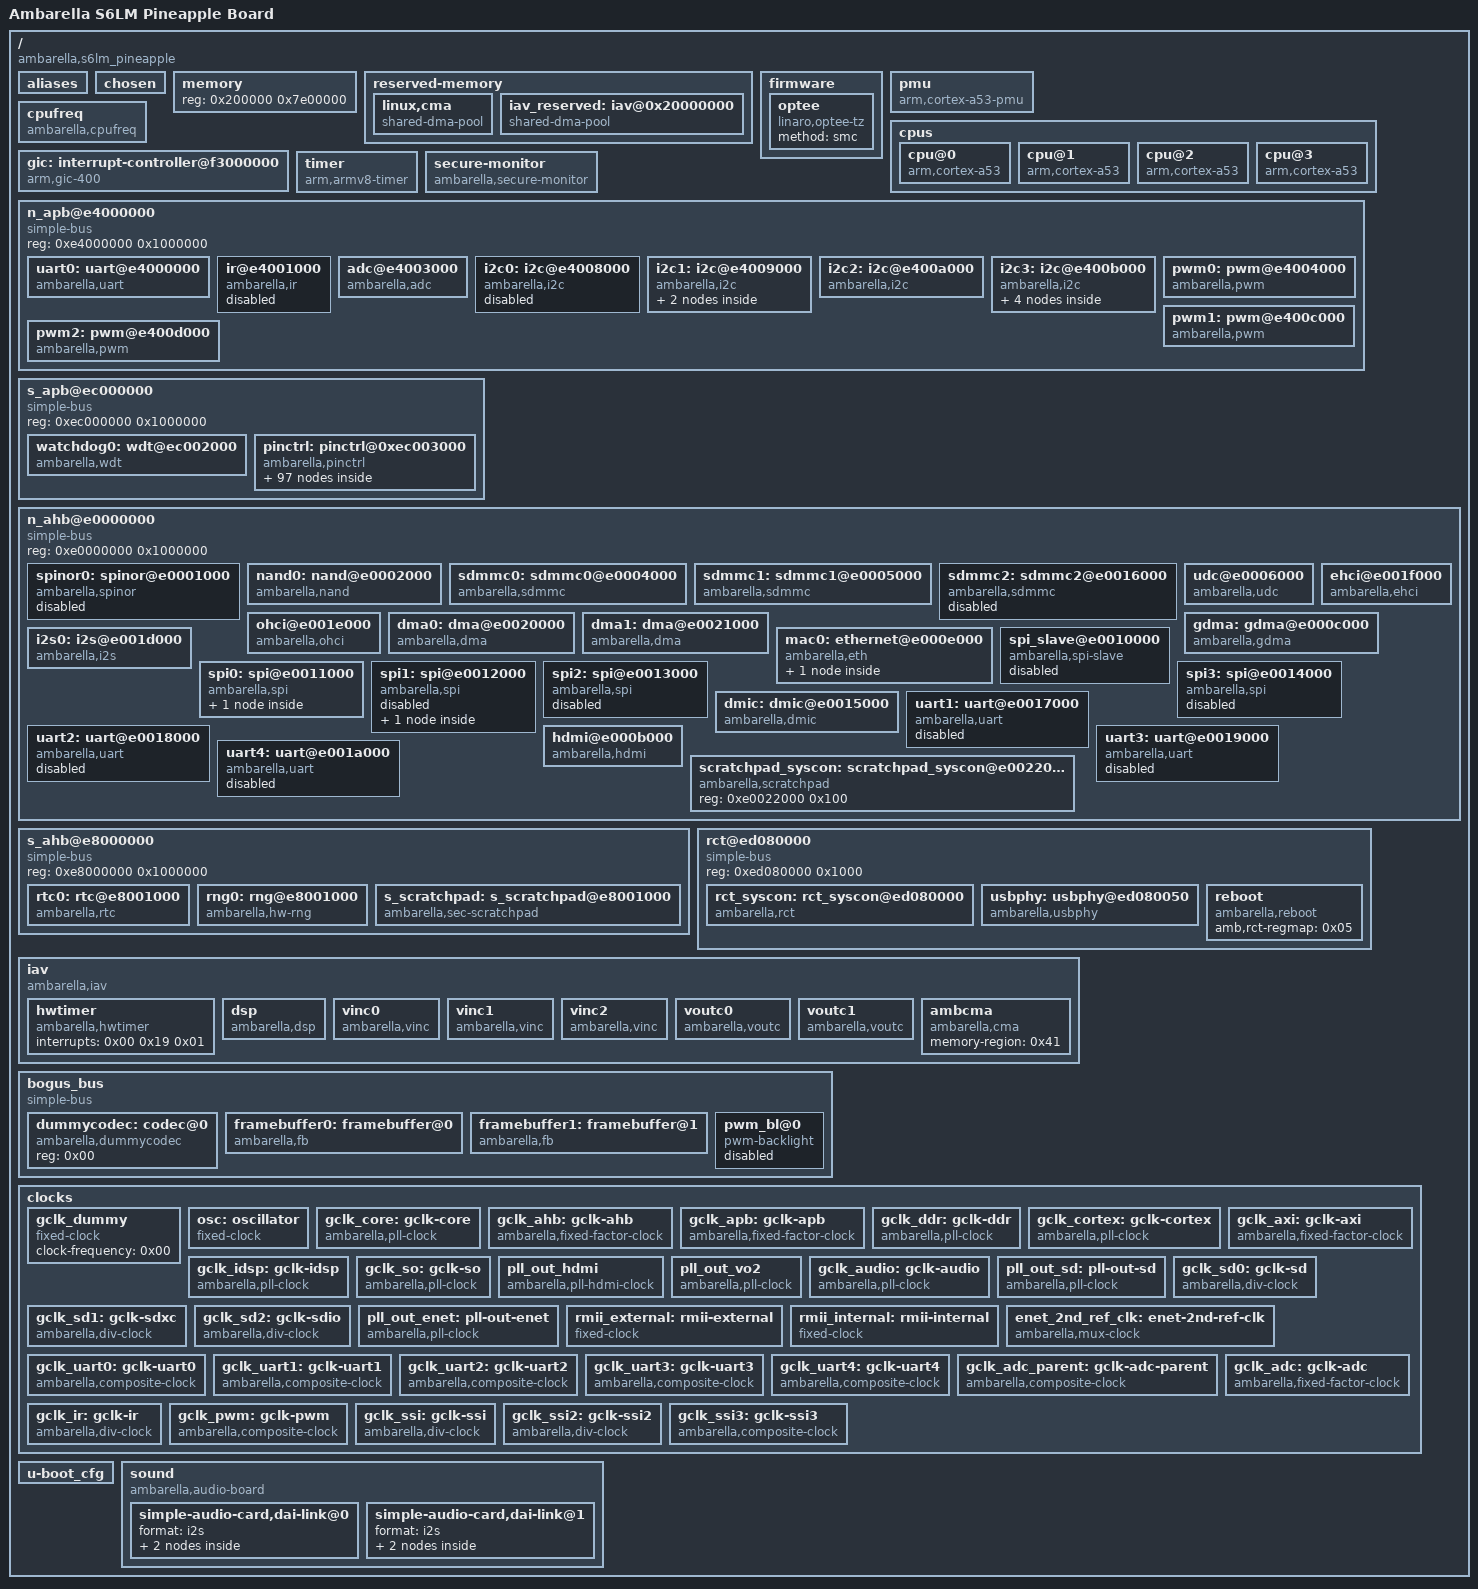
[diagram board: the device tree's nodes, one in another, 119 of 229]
/dts-v1/;

/ {
	compatible = "ambarella,s6lm_pineapple", "ambarella,s6lm";
	interrupt-parent = <0x01>;
	#address-cells = <0x01>;
	#size-cells = <0x01>;
	model = "Ambarella S6LM Pineapple Board";

	aliases {
		serial0 = "/n_apb@e4000000/uart@e4000000";
		serial1 = "/n_ahb@e0000000/uart@e0017000";
		serial2 = "/n_ahb@e0000000/uart@e0018000";
		serial3 = "/n_ahb@e0000000/uart@e0019000";
		serial4 = "/n_ahb@e0000000/uart@e001a000";
		nand = "/n_ahb@e0000000/nand@e0002000";
		sd0 = "/n_ahb@e0000000/sdmmc0@e0004000";
		spinor = "/n_ahb@e0000000/spinor@e0001000";
		i2c0 = "/n_apb@e4000000/i2c@e4008000";
		i2c1 = "/n_apb@e4000000/i2c@e4009000";
		i2c2 = "/n_apb@e4000000/i2c@e400a000";
		i2c3 = "/n_apb@e4000000/i2c@e400b000";
		spi0 = "/n_ahb@e0000000/spi@e0011000";
		spi1 = "/n_ahb@e0000000/spi@e0012000";
		spi2 = "/n_ahb@e0000000/spi@e0013000";
		spi3 = "/n_ahb@e0000000/spi@e0014000";
		ethernet0 = "/n_ahb@e0000000/ethernet@e000e000";
	};

	chosen {
		linux,stdout-path = "/n_apb@e4000000/uart@e4000000";
		stdout-path = "serial0";
		bootargs = "console=ttyS0 ubi.mtd=lnx root=ubi0:rootfs rw rootfstype=ubifs init=/linuxrc";
		ambarella,hibernate-lzo-enable;
	};

	memory {
		device_type = "memory";
		reg = <0x200000 0x7e00000>;
	};

	reserved-memory {
		#address-cells = <0x01>;
		#size-cells = <0x01>;
		ranges;

		linux,cma {
			compatible = "shared-dma-pool";
			reusable;
			size = <0x3000000>;
			linux,cma-default;
		};

		iav_reserved: iav@0x20000000 {
			compatible = "shared-dma-pool";
			reusable;
			reg = <0x20000000 0x20000000>;
			phandle = <0x41>;
		};
	};

	firmware {

		optee {
			compatible = "linaro,optee-tz";
			method = "smc";
		};
	};

	pmu {
		compatible = "arm,cortex-a53-pmu";
		interrupts = <0x00 0x04 0x04>, <0x00 0x05 0x04>, <0x00 0x06 0x04>, <0x00 0x07 0x04>;
	};

	cpus {
		#address-cells = <0x01>;
		#size-cells = <0x00>;

		cpu@0 {
			compatible = "arm,cortex-a53", "arm,armv8";
			device_type = "cpu";
			reg = <0x00>;
			enable-method = "spin-table";
		};

		cpu@1 {
			compatible = "arm,cortex-a53", "arm,armv8";
			device_type = "cpu";
			reg = <0x01>;
			enable-method = "spin-table";
		};

		cpu@2 {
			compatible = "arm,cortex-a53", "arm,armv8";
			device_type = "cpu";
			reg = <0x02>;
			enable-method = "spin-table";
		};

		cpu@3 {
			compatible = "arm,cortex-a53", "arm,armv8";
			device_type = "cpu";
			reg = <0x03>;
			enable-method = "spin-table";
		};
	};

	cpufreq {
		compatible = "ambarella,cpufreq";
		cpufreq-mask = <0x01>;
		amb,timer-freq-adjust-off;
		clocks = <0x02 0x03>;
		clock-names = "cortex_clk", "core_clk";
		clocks-frequency-cortex-core = <0xf6180 0x6f540>, <0xc7380 0x52080>, <0x927c0 0x3a980>;
	};

	gic: interrupt-controller@f3000000 {
		compatible = "arm,gic-400";
		#interrupt-cells = <0x03>;
		#address-cells = <0x00>;
		interrupt-controller;
		reg = <0xf3001000 0x1000>, <0xf3002000 0x2000>, <0xf3004000 0x2000>, <0xf3006000 0x2000>;
		interrupts = <0x01 0x09 0xf04>;
		phandle = <0x01>;
	};

	timer {
		compatible = "arm,armv8-timer";
		interrupts = <0x01 0x0d 0xf08>, <0x01 0x0e 0xf08>, <0x01 0x0b 0xf08>, <0x01 0x0a 0xf08>;
	};

	secure-monitor {
		compatible = "ambarella,secure-monitor";
		#address-cells = <0x01>;
		#size-cells = <0x00>;
		device = <0x04 0x05>;
		gpio = <0x23>;
	};

	n_apb@e4000000 {
		compatible = "simple-bus";
		#address-cells = <0x01>;
		#size-cells = <0x01>;
		reg = <0xe4000000 0x1000000>;
		ranges;

		uart0: uart@e4000000 {
			compatible = "ambarella,uart";
			reg = <0xe4000000 0x1000>;
			interrupts = <0x00 0x15 0x04>;
			pinctrl-names = "default";
			pinctrl-0 = <0x06>;
			clocks = <0x07>;
			status = "ok";
		};

		ir@e4001000 {
			compatible = "ambarella,ir";
			reg = <0xe4001000 0x1000>;
			interrupts = <0x00 0x14 0x04>;
			pinctrl-names = "default";
			pinctrl-0 = <0x08>;
			clocks = <0x09>;
			status = "disabled";
		};

		adc@e4003000 {
			compatible = "ambarella,adc";
			#io-channel-cells = <0x01>;
			reg = <0xe4003000 0x1000>;
			interrupts = <0x00 0x0d 0x04>;
			clock-frequency = <0x2dc6c0>;
			clocks = <0x0a>;
			amb,rct-regmap = <0x05>;
			amb,scaler-1v8 = <0x01>;
			status = "ok";
			amb,channels-used = <0x02>;
			amb,keymap = <0x1fff0dac 0x00>, <0x1dac09c4 0x8b>, <0x19c406a4 0x6a>, <0x16a40384 0x69>, <0x1384012c 0x6c>, <0x112c0000 0x67>;
		};

		i2c0: i2c@e4008000 {
			compatible = "ambarella,i2c";
			#address-cells = <0x01>;
			#size-cells = <0x00>;
			reg = <0xe4008000 0x1000>;
			interrupts = <0x00 0x0f 0x04>;
			pinctrl-names = "default";
			pinctrl-0 = <0x0b>;
			clocks = <0x0c>;
			clock-frequency = <0x186a0>;
			amb,i2c-class = <0x81>;
			status = "disabled";
		};

		i2c1: i2c@e4009000 {
			compatible = "ambarella,i2c";
			#address-cells = <0x01>;
			#size-cells = <0x00>;
			reg = <0xe4009000 0x1000>;
			interrupts = <0x00 0x10 0x04>;
			pinctrl-names = "default";
			pinctrl-0 = <0x0d>;
			clocks = <0x0c>;
			clock-frequency = <0x186a0>;
			amb,i2c-class = <0x08>;
			status = "ok";

			ak4951: codec@12 {
				compatible = "ambarella,ak4951";
				#sound-dai-cells = <0x00>;
				reg = <0x12>;
				gpios = <0x0e 0x0d 0x00>;
				pwr-gpios = <0x0e 0x0e 0x01>;
				phandle = <0x4b>;
			};

			ambvin0@01 {
				compatible = "ambarella,ambvin";
				reg = <0x01>;
			};
		};

		i2c2: i2c@e400a000 {
			compatible = "ambarella,i2c";
			#address-cells = <0x01>;
			#size-cells = <0x00>;
			reg = <0xe400a000 0x1000>;
			interrupts = <0x00 0x11 0x04>;
			clocks = <0x0c>;
			pinctrl-names = "default";
			pinctrl-0 = <0x0f>;
			clock-frequency = <0x186a0>;
			amb,i2c-class = <0x81>;
			status = "ok";
		};

		i2c3: i2c@e400b000 {
			compatible = "ambarella,i2c";
			#address-cells = <0x01>;
			#size-cells = <0x00>;
			reg = <0xe400b000 0x1000>;
			interrupts = <0x00 0x12 0x04>;
			clocks = <0x0c>;
			pinctrl-names = "default";
			pinctrl-0 = <0x10>;
			clock-frequency = <0x186a0>;
			amb,i2c-class = <0x81>;
			status = "ok";

			pca9539: pca9539@74 {
				compatible = "nxp,pca9539";
				reg = <0x74>;
				gpio-controller;
				interrupt-parent = <0x11>;
				interrupt-controller;
				#gpio-cells = <0x02>;
				interrupts = <0x0e 0x00>;
				phandle = <0x0e>;
			};

			it66121@4c {
				compatible = "it66121";
				reg = <0x4c>;
				rst_gpios = <0x0e 0x03 0x00>;
			};

			isl12022: rtc@6f {
				compatible = "isil,isl12022";
				reg = <0x6f>;
			};

			ambvin1@01 {
				compatible = "ambarella,ambvin";
				reg = <0x01>;
			};
		};

		pwm0: pwm@e4004000 {
			compatible = "ambarella,pwm";
			reg = <0xe4004000 0x1000>;
			clock-frequency = <0x1e8480>;
			clocks = <0x12>;
			#pwm-cells = <0x03>;
			phandle = <0x42>;
		};

		pwm1: pwm@e400c000 {
			compatible = "ambarella,pwm";
			reg = <0xe400c000 0x1000>;
			clock-frequency = <0x1e8480>;
			clocks = <0x12>;
			#pwm-cells = <0x03>;
		};

		pwm2: pwm@e400d000 {
			compatible = "ambarella,pwm";
			reg = <0xe400d000 0x1000>;
			clock-frequency = <0x1e8480>;
			clocks = <0x12>;
			#pwm-cells = <0x03>;
		};
	};

	s_apb@ec000000 {
		compatible = "simple-bus";
		#address-cells = <0x01>;
		#size-cells = <0x01>;
		reg = <0xec000000 0x1000000>;
		ranges;

		watchdog0: wdt@ec002000 {
			compatible = "ambarella,wdt";
			reg = <0xec002000 0x1000>;
			amb,rct-regmap = <0x05>;
			timeout-sec = <0x0f>;
			amb,secure-ctrl-bit = <0x31>;
		};

		pinctrl: pinctrl@0xec003000 {
			compatible = "ambarella,pinctrl", "simple-bus";
			#address-cells = <0x01>;
			#size-cells = <0x00>;
			reg = <0xec003000 0x1000>, <0xec004000 0x1000>, <0xec005000 0x1000>, <0xec000000 0x1000>, <0xe0022014 0x3c>, <0xed080314 0x13c>;
			reg-names = "gpio0", "gpio1", "gpio2", "iomux", "pad", "ds";
			#gpio-range-cells = <0x03>;
			amb,secure-ctrl-bit = <0x32 0x33 0x34 0x30>;
			phandle = <0x13>;

			gpio: gpio@0 {
				compatible = "ambarella,gpio";
				reg = <0x00>;
				interrupts = <0x00 0x2b 0x04>, <0x00 0x2c 0x04>, <0x00 0x2d 0x04>;
				gpio-controller;
				#gpio-cells = <0x02>;
				gpio-ranges = <0x13 0x00 0x00 0x56>;
				interrupt-controller;
				#interrupt-cells = <0x02>;
				phandle = <0x11>;
			};

			uart0_pins: uart0@0 {
				reg = <0x00>;
				amb,pinmux-ids = <0x100a 0x100b>;
				u-boot,dm-pre-reloc;
				phandle = <0x06>;
			};

			uart1_pins: uart1@0 {
				reg = <0x00>;
				amb,pinmux-ids = <0x1045 0x1046>;
				phandle = <0x31>;
			};

			uart1_flow_pins: uart1_flow@0 {
				reg = <0x00>;
				amb,pinmux-ids = <0x1047 0x1048>;
				phandle = <0x32>;
			};

			uart2_pins: uart2@0 {
				reg = <0x00>;
				amb,pinmux-ids = <0x1049 0x104a>;
				phandle = <0x34>;
			};

			uart2_flow_pins: uart2_flow@0 {
				reg = <0x00>;
				amb,pinmux-ids = <0x103e 0x103f>;
				phandle = <0x35>;
			};

			uart3_pins_a: uart3@0 {
				reg = <0x00>;
				amb,pinmux-ids = <0x1036 0x1037>;
			};

			uart3_pins_b: uart3@1 {
				reg = <0x01>;
				amb,pinmux-ids = <0x404b 0x404c>;
				phandle = <0x37>;
			};

			uart3_flow_pins_a: uart3_flow@0 {
				reg = <0x00>;
				amb,pinmux-ids = <0x1038 0x1039>;
			};

			uart3_flow_pins_b: uart3_flow@1 {
				reg = <0x01>;
				amb,pinmux-ids = <0x404d 0x404e>;
				phandle = <0x38>;
			};

			uart4_pins_a: uart4@0 {
				reg = <0x00>;
				amb,pinmux-ids = <0x103a 0x103b>;
				phandle = <0x3a>;
			};

			uart4_pins_b: uart4@1 {
				reg = <0x01>;
				amb,pinmux-ids = <0x404f 0x4050>;
			};

			uart4_flow_pins_a: uart4_flow@0 {
				reg = <0x00>;
				amb,pinmux-ids = <0x103c 0x103d>;
				phandle = <0x3b>;
			};

			uart4_flow_pins_b: uart4_flow@1 {
				reg = <0x01>;
				amb,pinmux-ids = <0x4051 0x4052>;
			};

			snand0_pins_a: snand0@0 {
				reg = <0x00>;
				amb,pinmux-ids = <0x2024 0x2025 0x202a 0x202b 0x202c 0x202d>;
				phandle = <0x17>;
			};

			snand0_pins_b: snand0@1 {
				reg = <0x01>;
				amb,pinmux-ids = <0x4036 0x4037 0x4038 0x4039 0x403a 0x403b>;
			};

			spinor0_pins_a: spinor0@0 {
				reg = <0x00>;
				amb,pinmux-ids = <0x3024 0x3025 0x302a 0x302b 0x302c 0x302d>;
				phandle = <0x14>;
			};

			spinor0_pins_b: spinor0@1 {
				reg = <0x01>;
				amb,pinmux-ids = <0x5036 0x5037 0x5038 0x5039 0x503a 0x503b>;
			};

			sdmmc0_cd_pin: sdmmc0_cd@0 {
				reg = <0x00>;
				amb,pinmux-ids = <0x2028>;
				phandle = <0x1a>;
			};

			sdmmc0_wp_pin: sdmmc0_wp@0 {
				reg = <0x00>;
				amb,pinmux-ids = <0x2029>;
				phandle = <0x1b>;
			};

			sdmmc0_reset_pin: sdmmc0_reset@0 {
				reg = <0x00>;
				amb,pinmux-ids = <0x203f>;
			};

			sdmmc0_pins_1bit: sdmmc0_1bit@0 {
				reg = <0x00>;
				amb,pinmux-ids = <0x2026 0x2027 0x202e>;
			};

			sdmmc0_pins_4bit: sdmmc0_4bit@0 {
				reg = <0x00>;
				amb,pinmux-ids = <0x2026 0x2027 0x202e 0x202f 0x2030 0x2031>;
			};

			sdmmc0_pins_8bit: sdmmc0_8bit@0 {
				reg = <0x00>;
				amb,pinmux-ids = <0x2026 0x2027 0x202e 0x202f 0x2030 0x2031 0x2032 0x2033 0x2034 0x2035>;
				phandle = <0x19>;
			};

			sdmmc1_cd_pin: sdmmc1_cd@0 {
				reg = <0x00>;
				amb,pinmux-ids = <0x203c>;
				phandle = <0x1e>;
			};

			sdmmc1_wp_pin: sdmmc1_wp@0 {
				reg = <0x00>;
				amb,pinmux-ids = <0x203d>;
				phandle = <0x1f>;
			};

			sdmmc1_reset_pin: sdmmc1_reset@0 {
				reg = <0x00>;
				amb,pinmux-ids = <0x203e>;
			};

			sdmmc1_pins_1bit: sdmmc1_1bit@0 {
				reg = <0x00>;
				amb,pinmux-ids = <0x2036 0x2037 0x2038>;
			};

			sdmmc1_pins_4bit: sdmmc1_4bit@0 {
				reg = <0x00>;
				amb,pinmux-ids = <0x2036 0x2037 0x2038 0x2039 0x203a 0x203b>;
				phandle = <0x1d>;
			};

			sdmmc2_cd_pin: sdmmc2_cd@0 {
				reg = <0x00>;
				amb,pinmux-ids = <0x1051>;
				phandle = <0x22>;
			};

			sdmmc2_wp_pin: sdmmc2_wp@0 {
				reg = <0x00>;
				amb,pinmux-ids = <0x1052>;
			};

			sdmmc2_pins_1bit: sdmmc2_1bit@0 {
				reg = <0x00>;
				amb,pinmux-ids = <0x104f 0x1050 0x104b>;
			};

			sdmmc2_pins_4bit: sdmmc2_4bit@0 {
				reg = <0x00>;
				amb,pinmux-ids = <0x104f 0x1050 0x104b 0x104c 0x104d 0x104e>;
				phandle = <0x21>;
			};

			rgmii_pins: eth0@0 {
				reg = <0x00>;
				amb,pinmux-ids = <0x4013 0x4014 0x4015 0x4016 0x4017 0x4018 0x4019 0x401a 0x401b 0x401c 0x501d 0x501e 0x4020 0x4021 0x4022>;
				phandle = <0x28>;
			};

			rmii_pins: eth0@1 {
				reg = <0x01>;
				amb,pinmux-ids = <0x3013 0x3014 0x3015 0x3018 0x3019 0x301c 0x501d 0x501e 0x301f 0x3020 0x3022>;
			};

			enet_2nd_ref_clk_pins_a: enet_2nd_ref_clk@0 {
				reg = <0x00>;
				amb,pinmux-ids = <0x3021>;
			};

			enet_2nd_ref_clk_pins_b: enet_2nd_ref_clk@1 {
				reg = <0x01>;
				amb,pinmux-ids = <0x3023>;
			};

			enet_2nd_ref_clk_pins_c: enet_2nd_ref_clk@2 {
				reg = <0x02>;
				amb,pinmux-ids = <0x501f>;
				phandle = <0x29>;
			};

			enet_2nd_ref_clk_pins_d: enet_2nd_ref_clk@3 {
				reg = <0x03>;
				amb,pinmux-ids = <0x4023>;
			};

			i2c0_pins_a: i2c0@0 {
				reg = <0x00>;
				amb,pinmux-ids = <0x303d 0x303e>;
				phandle = <0x0b>;
			};

			i2c0_pins_b: i2c0@1 {
				reg = <0x01>;
				amb,pinmux-ids = <0x400e 0x400f>;
			};

			i2c0_pins_c: i2c0@2 {
				reg = <0x02>;
				amb,pinmux-ids = <0x2018 0x2019>;
			};

			i2c1_pins_a: i2c1@0 {
				reg = <0x00>;
				amb,pinmux-ids = <0x304f 0x3050>;
				phandle = <0x0d>;
			};

			i2c1_pins_b: i2c1@1 {
				reg = <0x01>;
				amb,pinmux-ids = <0x2003 0x2004>;
			};

			i2c2_pins_a: i2c2@0 {
				reg = <0x00>;
				amb,pinmux-ids = <0x1053 0x1054>;
				phandle = <0x0f>;
			};

			i2c2_pins_b: i2c2@1 {
				reg = <0x01>;
				amb,pinmux-ids = <0x2001 0x2005>;
			};

			i2c2_pins_c: i2c2@2 {
				reg = <0x02>;
				amb,pinmux-ids = <0x3051 0x3052>;
			};

			i2c3_pins: i2c3@0 {
				reg = <0x00>;
				amb,pinmux-ids = <0x2008 0x2009>;
				phandle = <0x10>;
			};

			ir_pins_a: ir0@0 {
				reg = <0x00>;
				amb,pinmux-ids = <0x1000>;
				phandle = <0x08>;
			};

			ir_pins_b: ir0@1 {
				reg = <0x01>;
				amb,pinmux-ids = <0x503e>;
			};

			wdt_pins_a: wdt0@0 {
				reg = <0x00>;
				amb,pinmux-ids = <0x2000>;
			};

			wdt_pins_b: wdt0@1 {
				reg = <0x01>;
				amb,pinmux-ids = <0x3005>;
			};

			wdt_pins_c: wdt0@2 {
				reg = <0x02>;
				amb,pinmux-ids = <0x2007>;
			};

			wdt_pins_d: wdt0@3 {
				reg = <0x03>;
				amb,pinmux-ids = <0x2023>;
			};

			wdt_pins_e: wdt0@4 {
				reg = <0x04>;
				amb,pinmux-ids = <0x2042>;
			};

			i2s0_pins: i2s0@0 {
				reg = <0x00>;
				amb,pinmux-ids = <0x100f 0x1010 0x1011 0x1012>;
				phandle = <0x26>;
			};

			dmic0_pins: dmic_pins@0 {
				reg = <0x00>;
				amb,pinmux-ids = <0x4003 0x4004>;
			};

			dmic1_pins: dmic_pins@1 {
				reg = <0x01>;
				amb,pinmux-ids = <0x5008 0x5009>;
			};

			dmic2_pins: dmic_pins@2 {
				reg = <0x02>;
				amb,pinmux-ids = <0x300f 0x3010>;
			};

			usb_host0_pins_a: uhc0@0 {
				reg = <0x00>;
				amb,pinmux-ids = <0x504b 0x504c>;
			};

			usb_host0_pins_b: uhc0@1 {
				reg = <0x01>;
				amb,pinmux-ids = <0x3045 0x3047>;
				phandle = <0x3d>;
			};

			usb_host0_pins_c: uhc0@2 {
				reg = <0x02>;
				amb,pinmux-ids = <0x400a 0x400b>;
			};

			pwm0_pins_a: pwm0@0 {
				reg = <0x00>;
				amb,pinmux-ids = <0x100c>;
				phandle = <0x43>;
			};

			pwm0_pins_b: pwm0@1 {
				reg = <0x01>;
				amb,pinmux-ids = <0x5005>;
			};

			pwm0_pins_c: pwm0@2 {
				reg = <0x02>;
				amb,pinmux-ids = <0x2017>;
			};

			pwm1_pins: pwm1@0 {
				reg = <0x00>;
				amb,pinmux-ids = <0x100d>;
			};

			pwm2_pins: pwm2@0 {
				reg = <0x00>;
				amb,pinmux-ids = <0x100e>;
			};

			pwm3_pins_a: pwm3@0 {
				reg = <0x00>;
				amb,pinmux-ids = <0x201b>;
			};

			pwm3_pins_b: pwm3@1 {
				reg = <0x01>;
				amb,pinmux-ids = <0x3000>;
			};

			pwm4_pins_a: pwm4@0 {
				reg = <0x00>;
				amb,pinmux-ids = <0x3001>;
			};

			pwm4_pins_b: pwm4@1 {
				reg = <0x01>;
				amb,pinmux-ids = <0x201c>;
			};

			pwm5_pins_a: pwm5@0 {
				reg = <0x00>;
				amb,pinmux-ids = <0x3002>;
			};

			pwm5_pins_b: pwm5@1 {
				reg = <0x01>;
				amb,pinmux-ids = <0x201d>;
			};

			pwm6_pins_a: pwm6@0 {
				reg = <0x00>;
				amb,pinmux-ids = <0x3003>;
			};

			pwm6_pins_b: pwm6@1 {
				reg = <0x01>;
				amb,pinmux-ids = <0x201e>;
			};

			pwm7_pins_a: pwm7@0 {
				reg = <0x00>;
				amb,pinmux-ids = <0x3004>;
			};

			pwm7_pins_b: pwm7@1 {
				reg = <0x01>;
				amb,pinmux-ids = <0x201f>;
			};

			pwm7_pins_c: pwm7@2 {
				reg = <0x02>;
				amb,pinmux-ids = <0x504d>;
			};

			pwm8_pins_a: pwm8@0 {
				reg = <0x00>;
				amb,pinmux-ids = <0x2013>;
			};

			pwm8_pins_b: pwm8@1 {
				reg = <0x01>;
				amb,pinmux-ids = <0x2020>;
			};

			pwm8_pins_c: pwm8@2 {
				reg = <0x02>;
				amb,pinmux-ids = <0x504e>;
			};

			pwm9_pins_a: pwm9@0 {
				reg = <0x00>;
				amb,pinmux-ids = <0x2014>;
			};

			pwm9_pins_b: pwm9@1 {
				reg = <0x01>;
				amb,pinmux-ids = <0x2021>;
			};

			pwm9_pins_c: pwm9@2 {
				reg = <0x02>;
				amb,pinmux-ids = <0x504f>;
			};

			pwm10_pins: pwm10@0 {
				reg = <0x00>;
				amb,pinmux-ids = <0x2015>;
			};

			pwm11_pins: pwm11@0 {
				reg = <0x00>;
				amb,pinmux-ids = <0x2016>;
			};

			spi_slave_pins_a: spi_slave@0 {
				reg = <0x00>;
				amb,pinmux-ids = <0x4006 0x4007 0x4008 0x4009>;
				phandle = <0x2b>;
			};

			spi_slave_pins_b: spi_slave@1 {
				reg = <0x01>;
				amb,pinmux-ids = <0x304b 0x304c 0x304d 0x304e>;
			};

			spi0_pins_a: spi0@0 {
				reg = <0x00>;
				amb,pinmux-ids = <0x1001 0x1002 0x1003>;
				phandle = <0x2c>;
			};

			spi0_pins_b: spi0@1 {
				reg = <0x01>;
				amb,pinmux-ids = <0x204b 0x204c 0x204d>;
			};

			spi1_pins_a: spi1@0 {
				reg = <0x00>;
				amb,pinmux-ids = <0x200f 0x2010 0x2011>;
			};

			spi1_pins_b: spi1@1 {
				reg = <0x01>;
				amb,pinmux-ids = <0x3036 0x3037 0x3038>;
				phandle = <0x2d>;
			};

			spi1_pins_c: spi1@2 {
				reg = <0x02>;
				amb,pinmux-ids = <0x2045 0x2046 0x2047>;
			};

			spi1_pins_d: spi1@3 {
				reg = <0x03>;
				amb,pinmux-ids = <0x204f 0x2050 0x2051>;
			};

			spi2_pins: spi2@0 {
				reg = <0x00>;
				amb,pinmux-ids = <0x1006 0x1007 0x1008>;
				phandle = <0x2e>;
			};

			spi3_pins: spi3@0 {
				reg = <0x00>;
				amb,pinmux-ids = <0x500a 0x500b 0x500c>;
				phandle = <0x30>;
			};

			vout0_pins: vout0@0 {
				reg = <0x00>;
				amb,pinmux-ids = <0x1013 0x1014 0x1015 0x1016 0x1017 0x1018 0x1019 0x101a 0x101b 0x101c 0x101d 0x101e 0x101f 0x1020 0x1021 0x1022 0x3046 0x3048 0x3049 0x304a>;
				amb,pinconf-ids = <0xba0013 0xba0014 0xba0015 0xba0016 0xba0017 0xba0018 0xba0019 0xba001a 0xba001b 0xba001c 0xba001d 0xba001e 0xba001f 0xba0020 0xba0021 0xba0022 0xba0046 0xba0048 0xba0049 0xba004a>;
			};
		};
	};

	n_ahb@e0000000 {
		compatible = "simple-bus";
		#address-cells = <0x01>;
		#size-cells = <0x01>;
		reg = <0xe0000000 0x1000000>;
		ranges;

		spinor0: spinor@e0001000 {
			compatible = "ambarella,spinor";
			reg = <0xe0001000 0x1000>;
			interrupts = <0x00 0x49 0x04>;
			pinctrl-names = "default";
			pinctrl-0 = <0x14>;
			clocks = <0x15>;
			dmas = <0x16 0x05>, < 0x16 0x06>;
			dma-names = "tx", "rx";
			max-frequency = <0x2faf080>;
			status = "disabled";
		};

		nand0: nand@e0002000 {
			compatible = "ambarella,nand";
			#address-cells = <0x01>;
			#size-cells = <0x01>;
			reg = <0xe0002000 0x1000>;
			interrupts = <0x00 0x44 0x04>;
			amb,rct-regmap = <0x05>;
			pinctrl-names = "default";
			pinctrl-0 = <0x17>;
			clocks = <0x18>;
			nand-on-flash-bbt;
			amb,spinand-only;
		};

		sdmmc0: sdmmc0@e0004000 {
			compatible = "ambarella,sdmmc";
			#address-cells = <0x01>;
			#size-cells = <0x00>;
			reg = <0xe0004000 0x1000>;
			interrupts = <0x00 0x48 0x04>;
			pinctrl-names = "default";
			pinctrl-0 = <0x19 0x1a 0x1b>;
			clocks = <0x1c>;
			amb,rct-regmap = <0x05 0x4c0 0x4c4 0x664 0x4f0 0x00>;
			amb,tuning-tx-clk = <0x00>;
			max-frequency = <0x7270e00>;
			bus-width = <0x08>;
			cap-sdio-irq;
			cap-sd-highspeed;
			cap-mmc-highspeed;
			mmc-hs200-1_8v;
			pwr-gpios = <0x11 0x3f 0x01>;
			v18-gpios = <0x11 0x55 0x01>;
		};

		sdmmc1: sdmmc1@e0005000 {
			compatible = "ambarella,sdmmc";
			#address-cells = <0x01>;
			#size-cells = <0x00>;
			reg = <0xe0005000 0x1000>;
			interrupts = <0x00 0x47 0x04>;
			pinctrl-names = "default";
			pinctrl-0 = <0x1d 0x1e 0x1f>;
			clocks = <0x20>;
			amb,rct-regmap = <0x05 0x4c8 0x4cc 0x668 0x4f0 0x10>;
			amb,tuning-tx-clk = <0x00>;
			max-frequency = <0x7270e00>;
			bus-width = <0x04>;
			cap-sdio-irq;
			cap-sd-highspeed;
			cap-mmc-highspeed;
			mmc-hs200-1_8v;
			status = "ok";
			pwr-gpios = <0x11 0x3e 0x01>;
			v18-gpios = <0x11 0x06 0x01>;
		};

		sdmmc2: sdmmc2@e0016000 {
			compatible = "ambarella,sdmmc";
			#address-cells = <0x01>;
			#size-cells = <0x00>;
			reg = <0xe0016000 0x1000>;
			interrupts = <0x00 0x40 0x04>;
			pinctrl-names = "default";
			pinctrl-0 = <0x21 0x22>;
			clocks = <0x23>;
			max-frequency = <0x5b8d800>;
			bus-width = <0x04>;
			cap-sdio-irq;
			cap-sd-highspeed;
			cap-mmc-highspeed;
			mmc-hs200-1_8v;
			status = "disabled";
			pwr-gpios = <0x11 0x52 0x01>;
		};

		udc@e0006000 {
			compatible = "ambarella,udc";
			reg = <0xe0006000 0x2000>;
			interrupts = <0x00 0x43 0x04>;
			amb,rct-regmap = <0x05>;
			amb,scr-regmap = <0x24>;
			amb,usbphy = <0x25>;
		};

		ohci@e001e000 {
			compatible = "ambarella,ohci";
			reg = <0xe001e000 0x1000>;
			interrupts = <0x00 0x42 0x04>;
			amb,usbphy = <0x25>;
		};

		ehci@e001f000 {
			compatible = "ambarella,ehci";
			reg = <0xe001f000 0x1000>;
			interrupts = <0x00 0x41 0x04>;
			amb,usbphy = <0x25>;
		};

		dma0: dma@e0020000 {
			compatible = "ambarella,dma";
			reg = <0xe0020000 0x1000>, <0xe0022050 0x08>;
			interrupts = <0x00 0x53 0x04>;
			#dma-cells = <0x01>;
			dma-channels = <0x08>;
			dma-requests = <0x17>;
			phandle = <0x16>;
		};

		dma1: dma@e0021000 {
			compatible = "ambarella,dma";
			reg = <0xe0021000 0x1000>, <0xe0022058 0x08>;
			interrupts = <0x00 0x54 0x04>;
			#dma-cells = <0x01>;
			dma-channels = <0x08>;
			dma-requests = <0x17>;
			phandle = <0x2f>;
		};

		gdma: gdma@e000c000 {
			compatible = "ambarella,gdma";
			reg = <0xe000c000 0x400>;
			interrupts = <0x00 0x46 0x01>;
		};

		i2s0: i2s@e001d000 {
			compatible = "ambarella,i2s";
			#sound-dai-cells = <0x00>;
			reg = <0xe001d000 0x1000>;
			pinctrl-names = "default";
			pinctrl-0 = <0x26>;
			clocks = <0x27>;
			amb,i2s-channels = <0x02>;
			amb,default-mclk = <0xbb8000>;
			dmas = <0x16 0x15>, < 0x16 0x16>;
			dma-names = "tx", "rx";
			amb,ws-set;
			phandle = <0x4a>;
		};

		mac0: ethernet@e000e000 {
			compatible = "ambarella,eth";
			#address-cells = <0x01>;
			#size-cells = <0x00>;
			reg = <0xe000e000 0x2000>;
			interrupts = <0x00 0x3a 0x04>;
			pinctrl-names = "default";
			pinctrl-0 = <0x28 0x29>;
			phy-mode = "rgmii";
			amb,rct-regmap = <0x05>;
			amb,scr-regmap = <0x24>;
			amb,tx-ring-size = <0x20>;
			amb,rx-ring-size = <0x40>;
			amb,ipc-tx;
			amb,ipc-rx;
			amb,enhance;
			amb,ahb-12mhz-div = <0x05>;
			clock-names = "ptp_ref";
			clocks = <0x2a>;
			amb,ext-ref-clk;
			amb,tx-clk-invert;

			phy@0 {
				reg = <0x00>;
				rst-gpios = <0x0e 0x0b 0x00>;
				txen-skew-ps = <0x00>;
				rxdv-skew-ps = <0x00>;
				rxd0-skew-ps = <0x00>;
				rxd1-skew-ps = <0x00>;
				rxd2-skew-ps = <0x00>;
				rxd3-skew-ps = <0x00>;
				txd0-skew-ps = <0x00>;
				txd1-skew-ps = <0x00>;
				txd2-skew-ps = <0x00>;
				txd3-skew-ps = <0x00>;
			};
		};

		spi_slave@e0010000 {
			compatible = "ambarella,spi-slave";
			reg = <0xe0010000 0x1000>;
			interrupts = <0x00 0x50 0x04>;
			pinctrl-names = "default";
			pinctrl-0 = <0x2b>;
			status = "disabled";
		};

		spi0: spi@e0011000 {
			compatible = "ambarella,spi";
			#address-cells = <0x01>;
			#size-cells = <0x00>;
			reg = <0xe0011000 0x1000>;
			interrupts = <0x00 0x4a 0x04>;
			pinctrl-names = "default";
			pinctrl-0 = <0x2c>;
			amb,clk-freq = <0x337f980>;
			dmas = <0x16 0x01>, < 0x16 0x02>;
			dma-names = "tx", "rx";
			status = "ok";
			cs-gpios = <0x11 0x04 0x00>;

			ambvin0@0 {
				compatible = "ambarella,ambvin";
				reg = <0x00>;
				spi-max-frequency = <0xf4240>;
				spi-cpha;
				spi-cpol;
			};
		};

		spi1: spi@e0012000 {
			compatible = "ambarella,spi";
			#address-cells = <0x01>;
			#size-cells = <0x00>;
			reg = <0xe0012000 0x1000>;
			interrupts = <0x00 0x4b 0x04>;
			pinctrl-names = "default";
			pinctrl-0 = <0x2d>;
			amb,clk-freq = <0x337f980>;
			dmas = <0x16 0x03>, < 0x16 0x04>;
			dma-names = "tx", "rx";
			status = "disabled";
			cs-gpios = <0x11 0x3b 0x00>;

			gyro@0 {
				compatible = "ambarella,gyro";
				reg = <0x00>;
				spi-max-frequency = <0x1312d00>;
				spi-cpha;
				spi-cpol;
				irq-gpio = <0x11 0x05 0x00>;
			};
		};

		spi2: spi@e0013000 {
			compatible = "ambarella,spi";
			#address-cells = <0x01>;
			#size-cells = <0x00>;
			reg = <0xe0013000 0x1000>;
			interrupts = <0x00 0x4c 0x04>;
			pinctrl-names = "default";
			pinctrl-0 = <0x2e>;
			amb,clk-freq = <0x337f980>;
			dmas = <0x2f 0x11>, < 0x2f 0x12>;
			dma-names = "tx", "rx";
			status = "disabled";
		};

		spi3: spi@e0014000 {
			compatible = "ambarella,spi";
			#address-cells = <0x01>;
			#size-cells = <0x00>;
			reg = <0xe0014000 0x1000>;
			interrupts = <0x00 0x4d 0x04>;
			pinctrl-names = "default";
			pinctrl-0 = <0x30>;
			amb,clk-freq = <0x337f980>;
			dmas = <0x2f 0x13>, < 0x2f 0x14>;
			dma-names = "tx", "rx";
			status = "disabled";
		};

		dmic: dmic@e0015000 {
			compatible = "ambarella,dmic";
			reg = <0xe0015000 0x1000>;
			amb,scr-regmap = <0x24>;
			#sound-dai-cells = <0x00>;
			amb,custom-iir;
		};

		uart1: uart@e0017000 {
			compatible = "ambarella,uart";
			reg = <0xe0017000 0x1000>;
			interrupts = <0x00 0x3b 0x04>;
			pinctrl-names = "default";
			pinctrl-0 = <0x31 0x32>;
			clocks = <0x33>;
			amb,msr-used;
			amb,txdma-used;
			amb,rxdma-used;
			dmas = <0x16 0x09>, < 0x16 0x0a>;
			dma-names = "tx", "rx";
			status = "disabled";
		};

		uart2: uart@e0018000 {
			compatible = "ambarella,uart";
			reg = <0xe0018000 0x1000>;
			interrupts = <0x00 0x3c 0x04>;
			pinctrl-names = "default";
			pinctrl-0 = <0x34 0x35>;
			clocks = <0x36>;
			amb,msr-used;
			amb,txdma-used;
			amb,rxdma-used;
			dmas = <0x2f 0x0b>, < 0x2f 0x0c>;
			dma-names = "tx", "rx";
			status = "disabled";
		};

		uart3: uart@e0019000 {
			compatible = "ambarella,uart";
			reg = <0xe0019000 0x1000>;
			interrupts = <0x00 0x3d 0x04>;
			pinctrl-names = "default";
			pinctrl-0 = <0x37 0x38>;
			clocks = <0x39>;
			amb,msr-used;
			amb,txdma-used;
			amb,rxdma-used;
			dmas = <0x2f 0x0d>, < 0x2f 0x0e>;
			dma-names = "tx", "rx";
			status = "disabled";
		};

		uart4: uart@e001a000 {
			compatible = "ambarella,uart";
			reg = <0xe001a000 0x1000>;
			interrupts = <0x00 0x3e 0x04>;
			pinctrl-names = "default";
			pinctrl-0 = <0x3a 0x3b>;
			clocks = <0x3c>;
			amb,msr-used;
			amb,txdma-used;
			amb,rxdma-used;
			dmas = <0x2f 0x0f>, < 0x2f 0x10>;
			dma-names = "tx", "rx";
			status = "disabled";
		};

		hdmi@e000b000 {
			compatible = "ambarella,hdmi";
			reg = <0xe000b000 0x1000>;
			interrupts = <0x00 0x55 0x04>;
			interrupt-names = "hdmi";
			amb,hdmiphy = <0xed080010>;
			amb,hdmi-version = <0x14>;
			amb,i2c-adapter = <0x02>;
		};

		scratchpad_syscon: scratchpad_syscon@e0022000 {
			compatible = "ambarella,scratchpad", "syscon";
			reg = <0xe0022000 0x100>;
			phandle = <0x24>;
		};
	};

	s_ahb@e8000000 {
		compatible = "simple-bus";
		#address-cells = <0x01>;
		#size-cells = <0x01>;
		reg = <0xe8000000 0x1000000>;
		ranges;

		rtc0: rtc@e8001000 {
			compatible = "ambarella,rtc";
			reg = <0xe8001000 0x1000>;
			amb,secure-ctrl-bit = <0x1f>;
		};

		rng0: rng@e8001000 {
			compatible = "ambarella,hw-rng";
			reg = <0xe8001000 0x14>;
			amb,rct-regmap = <0x05>;
			amb,secure-ctrl-bit = <0x1f>;
		};

		s_scratchpad: s_scratchpad@e8001000 {
			compatible = "ambarella,sec-scratchpad";
			reg = <0xe8001000 0x1000>;
			amb,secure-ctrl-bit = <0x1f>;
			amb,secure-reg-ro = <0xe80010a0 0x0c>, <0xe80010b4 0x04>;
			phandle = <0x04>;
		};
	};

	rct@ed080000 {
		compatible = "simple-bus";
		#address-cells = <0x01>;
		#size-cells = <0x01>;
		reg = <0xed080000 0x1000>;
		ranges;

		rct_syscon: rct_syscon@ed080000 {
			compatible = "ambarella,rct", "syscon";
			reg = <0xed080000 0x1000>;
			amb,secure-ctrl-bit = <0x44>;
			amb,secure-reg-ro = <0xed080000 0x08>, <0xed080034 0x04>, <0xed08008c 0x04>, <0xed0800dc 0x10>, <0xed080100 0x1c>, <0xed080148 0x04>, <0xed080174 0x0c>, <0xed0801f4 0x04>, <0xed080220 0x0c>, <0xed080264 0x14>, <0xed0802dc 0x10>, <0xed0803f8 0x08>, <0xed0804f8 0x04>, <0xed08070c 0x08>, <0xed080794 0x04>;
			phandle = <0x05>;
		};

		usbphy: usbphy@ed080050 {
			compatible = "ambarella,usbphy";
			reg = <0xed080050 0x04 0xe0022060 0x04 0xed0802c0 0x04>;
			amb,host-phy-num = <0x01>;
			amb,ocp-polarity = <0x00>;
			pinctrl-names = "default";
			pinctrl-0 = <0x3d>;
			hub-gpios = <0x0e 0x0a 0x00>;
			phandle = <0x25>;
		};

		reboot {
			compatible = "ambarella,reboot";
			amb,rct-regmap = <0x05>;
		};
	};

	iav {
		compatible = "ambarella,iav";
		#address-cells = <0x01>;
		#size-cells = <0x01>;

		hwtimer {
			compatible = "ambarella,hwtimer";
			interrupts = <0x00 0x19 0x01>;
			interrupt-names = "hwtimer";
		};

		dsp {
			compatible = "ambarella,dsp";
			interrupts = <0x00 0x8d 0x01 0x00 0x8e 0x01 0x00 0x8f 0x01 0x00 0x90 0x01>;
			interrupt-names = "vdsp", "vapi", "venc", "vcap";
		};

		vinc0 {
			compatible = "ambarella,vinc";
			interrupts = <0x00 0x6e 0x01 0x00 0x6f 0x01 0x00 0x70 0x01>;
			interrupt-names = "idsp", "idsp_sof", "idsp_last_pixel";
			clocks = <0x3e>;
			vinrst-gpios = <0x11 0x42 0x00>;
		};

		vinc1 {
			compatible = "ambarella,vinc";
			interrupts = <0x00 0x87 0x01 0x00 0x88 0x01 0x00 0x89 0x01>;
			interrupt-names = "idsp", "idsp_sof", "idsp_last_pixel";
			clocks = <0x3e>;
			vinrst-gpios = <0x11 0x07 0x00>;
		};

		vinc2 {
			compatible = "ambarella,vinc";
			interrupts = <0x00 0x72 0x01 0x00 0x73 0x01 0x00 0x74 0x01>;
			interrupt-names = "idsp", "idsp_sof", "idsp_last_pixel";
			clocks = <0x3e>;
		};

		voutc0 {
			compatible = "ambarella,voutc";
			output-type = "digital";
			interrupts = <0x00 0x59 0x01>;
			interrupt-names = "vout0";
			rct-regmap = <0x05>;
			pinctrl-names;
			pinctrl-0;
			clocks = <0x3f>;
		};

		voutc1 {
			compatible = "ambarella,voutc";
			output-type = "hdmi", "cvbs";
			interrupts = <0x00 0x58 0x01>;
			interrupt-names = "vout1";
			rct-regmap = <0x05>;
			clocks = <0x40>;
		};

		ambcma {
			compatible = "ambarella,cma";
			memory-region = <0x41>;
		};
	};

	bogus_bus {
		compatible = "simple-bus";
		#address-cells = <0x01>;
		#size-cells = <0x00>;

		dummycodec: codec@0 {
			compatible = "ambarella,dummycodec";
			reg = <0x00>;
			#sound-dai-cells = <0x00>;
			phandle = <0x4c>;
		};

		framebuffer0: framebuffer@0 {
			compatible = "ambarella,fb";
			reg = <0x00>;
			amb,vout-id = <0x00>;
			amb,format = "rgb565";
		};

		framebuffer1: framebuffer@1 {
			compatible = "ambarella,fb";
			reg = <0x01>;
			amb,vout-id = <0x01>;
			amb,format = "rgb565";
		};

		pwm_bl@0 {
			compatible = "pwm-backlight";
			reg = <0x00>;
			pwms = <0x42 0x00 0x9c40 0x00>;
			pinctrl-names = "default";
			pinctrl-0 = <0x43>;
			brightness-levels = <0x00 0x04 0x08 0x10 0x20 0x40 0x80 0xff>;
			default-brightness-level = <0x07>;
			status = "disabled";
		};
	};

	clocks {
		#address-cells = <0x01>;
		#size-cells = <0x01>;
		ranges;

		gclk_dummy: gclk_dummy {
			#clock-cells = <0x00>;
			compatible = "fixed-clock";
			clock-frequency = <0x00>;
		};

		osc: oscillator {
			compatible = "fixed-clock";
			#clock-cells = <0x00>;
			clock-frequency = <0x16e3600>;
			clock-output-names = "osc";
			phandle = <0x2a>;
		};

		gclk_core: gclk-core {
			#clock-cells = <0x00>;
			compatible = "ambarella,pll-clock";
			reg = <0xed080000 0x04>, <0xed080004 0x04>, <0xed080100 0x04>, <0xed080104 0x04>, <0x00 0x00>, <0x00 0x00>;
			clocks = <0x2a>;
			clock-output-names = "gclk_core";
			phandle = <0x03>;
		};

		gclk_ahb: gclk-ahb {
			#clock-cells = <0x00>;
			compatible = "ambarella,fixed-factor-clock";
			clocks = <0x03>;
			clock-output-names = "gclk_ahb";
			clock-mult = <0x01>;
			clock-div = <0x02>;
		};

		gclk_apb: gclk-apb {
			#clock-cells = <0x00>;
			compatible = "ambarella,fixed-factor-clock";
			clocks = <0x03>;
			clock-output-names = "gclk_apb";
			clock-mult = <0x01>;
			clock-div = <0x04>;
			phandle = <0x0c>;
		};

		gclk_ddr: gclk-ddr {
			#clock-cells = <0x00>;
			compatible = "ambarella,pll-clock";
			reg = <0xed0800dc 0x04>, <0xed0800e0 0x04>, <0xed080110 0x04>, <0xed080114 0x04>, <0x00 0x00>, <0x00 0x00>;
			clocks = <0x2a>;
			clock-output-names = "gclk_ddr";
			amb,fix-divider = <0x02>;
		};

		gclk_cortex: gclk-cortex {
			#clock-cells = <0x00>;
			compatible = "ambarella,pll-clock";
			reg = <0xed080264 0x04>, <0xed080268 0x04>, <0xed08026c 0x04>, <0xed080270 0x04>, <0x00 0x00>, <0x00 0x00>;
			clocks = <0x2a>;
			clock-output-names = "gclk_cortex";
			phandle = <0x02>;
		};

		gclk_axi: gclk-axi {
			#clock-cells = <0x00>;
			compatible = "ambarella,fixed-factor-clock";
			clocks = <0x02>;
			clock-output-names = "gclk_axi";
			clock-mult = <0x01>;
			clock-div = <0x03>;
		};

		gclk_idsp: gclk-idsp {
			#clock-cells = <0x00>;
			compatible = "ambarella,pll-clock";
			reg = <0xed0800e4 0x04>, <0xed0800e8 0x04>, <0xed080108 0x04>, <0xed08010c 0x04>, <0x00 0x00>, <0xed0801f4 0x04>;
			clocks = <0x2a>;
			clock-output-names = "gclk_idsp";
			amb,extra-post-scaler;
			phandle = <0x47>;
		};

		gclk_so: gclk-so {
			#clock-cells = <0x00>;
			compatible = "ambarella,pll-clock";
			reg = <0xed080024 0x04>, <0xed080028 0x04>, <0xed08011c 0x04>, <0xed080120 0x04>, <0xed08004c 0x04>, <0xed080030 0x04>;
			clocks = <0x2a>;
			clock-output-names = "gclk_so";
			assigned-clocks = <0x3e>;
			assigned-clock-rates = <0x2367b88>;
			amb,extra-pre-scaler;
			amb,extra-post-scaler;
			amb,frac-mode;
			phandle = <0x3e>;
		};

		pll_out_hdmi: pll_out_hdmi {
			#clock-cells = <0x00>;
			compatible = "ambarella,pll-hdmi-clock";
			reg = <0xed080164 0x04>, <0xed080168 0x04>, <0xed080150 0x04>, <0xed080154 0x04>, <0xed080170 0x04>, <0x00 0x00>;
			clocks = <0x2a>;
			clock-output-names = "pll_out_hdmi";
			assigned-clocks = <0x40>;
			assigned-clock-rates = <0x1017df80>;
			amb,extra-pre-scaler;
			amb,frac-mode;
			amb,ctrl2-val = <0x30520000>;
			amb,ctrl3-val = <0x88004>;
			amb,min-vco = <0x9c4>;
			phandle = <0x40>;
		};

		pll_out_vo2: pll_out_vo2 {
			#clock-cells = <0x00>;
			compatible = "ambarella,pll-clock";
			reg = <0xed0800c0 0x04>, <0xed0800c4 0x04>, <0xed08013c 0x04>, <0xed080140 0x04>, <0xed0800c8 0x04>, <0x00 0x00>;
			clocks = <0x2a>;
			clock-output-names = "pll_out_vo2";
			assigned-clocks = <0x3f>;
			assigned-clock-rates = <0x16e3600>;
			amb,extra-pre-scaler;
			amb,frac-mode;
			phandle = <0x3f>;
		};

		gclk_audio: gclk-audio {
			#clock-cells = <0x00>;
			compatible = "ambarella,pll-clock";
			reg = <0xed080054 0x04>, <0xed080058 0x04>, <0xed080124 0x04>, <0xed08012c 0x04>, <0xed080060 0x04>, <0xed08005c 0x04>;
			clocks = <0x2a>;
			clock-output-names = "gclk_audio";
			assigned-clocks = <0x27>;
			assigned-clock-rates = <0xbb8000>;
			amb,extra-pre-scaler;
			amb,extra-post-scaler;
			amb,frac-mode;
			phandle = <0x27>;
		};

		pll_out_sd: pll-out-sd {
			#clock-cells = <0x00>;
			compatible = "ambarella,pll-clock";
			reg = <0xed0804ac 0x04>, <0xed0804b0 0x04>, <0xed0804b4 0x04>, <0xed0804b8 0x04>, <0x00 0x00>, <0x00 0x00>;
			clocks = <0x2a>;
			clock-output-names = "pll_out_sd";
			phandle = <0x44>;
		};

		gclk_sd0: gclk-sd {
			#clock-cells = <0x00>;
			compatible = "ambarella,div-clock";
			reg = <0xed08000c 0x04>;
			clocks = <0x44>;
			clock-output-names = "gclk_sd0";
			amb,div-width = <0x10>;
			amb,div-shift = <0x00>;
			phandle = <0x1c>;
		};

		gclk_sd1: gclk-sdxc {
			#clock-cells = <0x00>;
			compatible = "ambarella,div-clock";
			reg = <0xed080430 0x04>;
			clocks = <0x44>;
			clock-output-names = "gclk_sd1";
			amb,div-width = <0x10>;
			amb,div-shift = <0x00>;
			phandle = <0x20>;
		};

		gclk_sd2: gclk-sdio {
			#clock-cells = <0x00>;
			compatible = "ambarella,div-clock";
			reg = <0xed080434 0x04>;
			clocks = <0x44>;
			clock-output-names = "gclk_sd2";
			amb,div-width = <0x10>;
			amb,div-shift = <0x00>;
			phandle = <0x23>;
		};

		pll_out_enet: pll-out-enet {
			#clock-cells = <0x00>;
			compatible = "ambarella,pll-clock";
			reg = <0xed080520 0x04>, <0xed080524 0x04>, <0xed080528 0x04>, <0xed08052c 0x04>, <0x00 0x00>, <0x00 0x00>;
			clocks = <0x2a>;
			clock-output-names = "pll_out_enet";
			phandle = <0x18>;
		};

		rmii_external: rmii-external {
			compatible = "fixed-clock";
			#clock-cells = <0x00>;
			clock-frequency = <0x17d7840>;
			clock-output-names = "rmii_external";
			phandle = <0x45>;
		};

		rmii_internal: rmii-internal {
			compatible = "fixed-clock";
			#clock-cells = <0x00>;
			clock-frequency = <0x2faf080>;
			clock-output-names = "rmii_internal";
			phandle = <0x46>;
		};

		enet_2nd_ref_clk: enet-2nd-ref-clk {
			#clock-cells = <0x00>;
			compatible = "ambarella,mux-clock";
			reg = <0xed0806b8 0x04>;
			clocks = <0x45>, < 0x46>;
			clock-output-names = "enet_2nd_ref_clk";
		};

		gclk_uart0: gclk-uart0 {
			#clock-cells = <0x00>;
			compatible = "ambarella,composite-clock";
			reg = <0xed080038 0x04>, <0xed0801c8 0x04>;
			clocks = <0x2a>, < 0x03>, < 0x18>, < 0x44>;
			clock-output-names = "gclk_uart0";
			assigned-clocks = <0x07>;
			assigned-clock-parents = <0x2a>;
			assigned-clock-rates = <0x16e3600>;
			amb,div-width = <0x18>;
			amb,div-shift = <0x00>;
			phandle = <0x07>;
		};

		gclk_uart1: gclk-uart1 {
			#clock-cells = <0x00>;
			compatible = "ambarella,composite-clock";
			reg = <0xed080714 0x04>, <0xed08072c 0x04>;
			clocks = <0x2a>, < 0x03>, < 0x18>, < 0x44>;
			clock-output-names = "gclk_uart1";
			assigned-clocks = <0x33>;
			assigned-clock-parents = <0x2a>;
			assigned-clock-rates = <0x16e3600>;
			amb,div-width = <0x18>;
			amb,div-shift = <0x00>;
			phandle = <0x33>;
		};

		gclk_uart2: gclk-uart2 {
			#clock-cells = <0x00>;
			compatible = "ambarella,composite-clock";
			reg = <0xed080718 0x04>, <0xed080730 0x04>;
			clocks = <0x2a>, < 0x03>, < 0x18>, < 0x44>;
			clock-output-names = "gclk_uart2";
			assigned-clocks = <0x36>;
			assigned-clock-parents = <0x2a>;
			assigned-clock-rates = <0x16e3600>;
			amb,div-width = <0x18>;
			amb,div-shift = <0x00>;
			phandle = <0x36>;
		};

		gclk_uart3: gclk-uart3 {
			#clock-cells = <0x00>;
			compatible = "ambarella,composite-clock";
			reg = <0xed08071c 0x04>, <0xed080734 0x04>;
			clocks = <0x2a>, < 0x03>, < 0x18>, < 0x44>;
			clock-output-names = "gclk_uart3";
			assigned-clocks = <0x39>;
			assigned-clock-parents = <0x2a>;
			assigned-clock-rates = <0x16e3600>;
			amb,div-width = <0x18>;
			amb,div-shift = <0x00>;
			phandle = <0x39>;
		};

		gclk_uart4: gclk-uart4 {
			#clock-cells = <0x00>;
			compatible = "ambarella,composite-clock";
			reg = <0xed080720 0x04>, <0xed080738 0x04>;
			clocks = <0x2a>, < 0x03>, < 0x18>, < 0x44>;
			clock-output-names = "gclk_uart4";
			assigned-clocks = <0x3c>;
			assigned-clock-parents = <0x2a>;
			assigned-clock-rates = <0x16e3600>;
			amb,div-width = <0x18>;
			amb,div-shift = <0x00>;
			phandle = <0x3c>;
		};

		gclk_adc_parent: gclk-adc-parent {
			#clock-cells = <0x00>;
			compatible = "ambarella,composite-clock";
			reg = <0xed08009c 0x04>, <0xed0801d0 0x04>;
			clocks = <0x2a>, < 0x47>, < 0x18>;
			clock-output-names = "gclk_adc_parent";
			amb,div-width = <0x10>;
			amb,div-shift = <0x00>;
			phandle = <0x48>;
		};

		gclk_adc: gclk-adc {
			#clock-cells = <0x00>;
			compatible = "ambarella,fixed-factor-clock";
			clocks = <0x48>;
			clock-output-names = "gclk_adc";
			clock-mult = <0x01>;
			clock-div = <0x02>;
			phandle = <0x0a>;
		};

		gclk_ir: gclk-ir {
			#clock-cells = <0x00>;
			compatible = "ambarella,div-clock";
			reg = <0xed080044 0x04>;
			clocks = <0x2a>;
			clock-output-names = "gclk_ir";
			amb,div-width = <0x18>;
			amb,div-shift = <0x00>;
			phandle = <0x09>;
		};

		gclk_pwm: gclk-pwm {
			#clock-cells = <0x00>;
			compatible = "ambarella,composite-clock";
			reg = <0xed080084 0x04>, <0xed0801c4 0x04>;
			clocks = <0x0c>, < 0x02>, < 0x18>, < 0x2a>;
			clock-output-names = "gclk_pwm";
			assigned-clocks = <0x12>;
			assigned-clock-parents = <0x18>;
			amb,div-width = <0x18>;
			amb,div-shift = <0x00>;
			phandle = <0x12>;
		};

		gclk_ssi: gclk-ssi {
			#clock-cells = <0x00>;
			compatible = "ambarella,div-clock";
			reg = <0xed08003c 0x04>;
			clocks = <0x03>;
			clock-output-names = "gclk_ssi";
			amb,div-width = <0x18>;
			amb,div-shift = <0x00>;
			phandle = <0x49>;
		};

		gclk_ssi2: gclk-ssi2 {
			#clock-cells = <0x00>;
			compatible = "ambarella,div-clock";
			reg = <0xed0800ec 0x04>;
			clocks = <0x03>;
			clock-output-names = "gclk_ssi2";
			amb,div-width = <0x18>;
			amb,div-shift = <0x00>;
		};

		gclk_ssi3: gclk-ssi3 {
			#clock-cells = <0x00>;
			compatible = "ambarella,composite-clock";
			reg = <0xed080518 0x04>, <0xed08051c 0x04>;
			clocks = <0x18>, < 0x03>, < 0x49>, < 0x2a>;
			clock-output-names = "gclk_ssi3";
			amb,div-width = <0x18>;
			amb,div-shift = <0x00>;
			phandle = <0x15>;
		};
	};

	u-boot_cfg {
		ram-size = <0x40000000>;
		reloc-top = <0x20000000>;
	};

	sound {
		compatible = "ambarella,audio-board";
		simple-audio-card,name = "ak4951 @ AMBEVK";
		simple-audio-card,mclk-fs = <0x100>;
		simple-audio-card,widgets = "Speaker", "Speaker", "Headphone", "HP Jack", "Line", "Line In", "Line", "Line Out", "Microphone", "Mic Internal", "Microphone", "Mic External";
		simple-audio-card,routing = "LIN2", "Mic Bias", "RIN2", "Mic Bias", "Mic Bias", "Mic Internal", "LIN3", "Line In", "RIN3", "Line In", "Line Out", "SPKLO", "HP Jack", "HPL", "HP Jack", "HPR", "Speaker", "SPKLO";

		simple-audio-card,dai-link@0 {
			format = "i2s";

			cpu {
				sound-dai = <0x4a>;
			};

			codec {
				sound-dai = <0x4b>;
			};
		};

		simple-audio-card,dai-link@1 {
			format = "i2s";

			cpu {
				sound-dai = <0x4a>;
			};

			codec {
				sound-dai = <0x4c>;
			};
		};
	};
};
